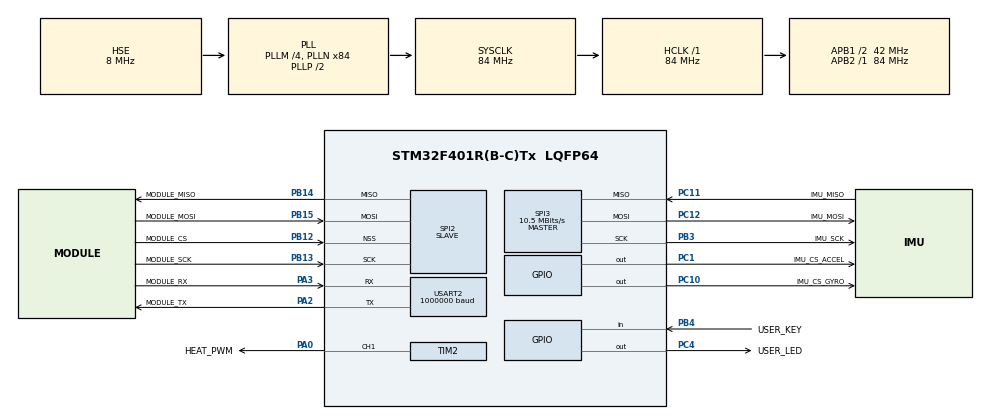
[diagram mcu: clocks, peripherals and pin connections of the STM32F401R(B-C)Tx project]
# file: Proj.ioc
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Dma.Request0=SPI2_RX
Dma.Request1=SPI2_TX
Dma.SPI2_RX.0.Direction=DMA_PERIPH_TO_MEMORY
Dma.SPI2_RX.0.FIFOMode=DMA_FIFOMODE_DISABLE
Dma.SPI2_RX.0.Instance=DMA1_Stream3
Dma.SPI2_RX.0.MemDataAlignment=DMA_MDATAALIGN_BYTE
Dma.SPI2_RX.0.MemInc=DMA_MINC_ENABLE
Dma.SPI2_RX.0.Mode=DMA_NORMAL
Dma.SPI2_RX.0.PeriphDataAlignment=DMA_PDATAALIGN_BYTE
Dma.SPI2_RX.0.PeriphInc=DMA_PINC_DISABLE
Dma.SPI2_RX.0.Priority=DMA_PRIORITY_LOW
Dma.SPI2_TX.1.Direction=DMA_MEMORY_TO_PERIPH
Dma.SPI2_TX.1.FIFOMode=DMA_FIFOMODE_DISABLE
Dma.SPI2_TX.1.Instance=DMA1_Stream4
Dma.SPI2_TX.1.MemDataAlignment=DMA_MDATAALIGN_BYTE
Dma.SPI2_TX.1.MemInc=DMA_MINC_ENABLE
Dma.SPI2_TX.1.Mode=DMA_NORMAL
Dma.SPI2_TX.1.PeriphDataAlignment=DMA_PDATAALIGN_BYTE
Dma.SPI2_TX.1.PeriphInc=DMA_PINC_DISABLE
Dma.SPI2_TX.1.Priority=DMA_PRIORITY_LOW
FREERTOS.INCLUDE_vTaskDelayUntil=1
FREERTOS.Tasks01=defaultTask,0,128,StartDefaultTask,Default,NULL,Dynamic,NULL,NULL;UartComm,0,512,UartCommTask,As weak,NULL,Static,UartCommBuffer,UartCommControlBlock;SPIComm,0,512,SPICommTask,As weak,NULL,Static,SPICommBuffer,SPICommControlBlock;Inertial,2,1024,InertialTask,As weak,NULL,Static,InertialBuffer,InertialControlBlock
FREERTOS.configENABLE_FPU=1
Mcu.Family=STM32F4
Mcu.Name=STM32F401R(B-C)Tx
Mcu.Package=LQFP64
NVIC.DMA1_Stream3_IRQn=true\:5\:0\:false\:false\:true\:true\:false\:true\:true
NVIC.DMA1_Stream4_IRQn=true\:5\:0\:false\:false\:true\:true\:false\:true\:true
NVIC.PriorityGroup=NVIC_PRIORITYGROUP_4
NVIC.TIM1_TRG_COM_TIM11_IRQn=true\:5\:0\:false\:false\:true\:true\:true\:true\:true
NVIC.TIM1_UP_TIM10_IRQn=true\:15\:0\:false\:false\:true\:false\:false\:true\:true
NVIC.TimeBase=TIM1_UP_TIM10_IRQn
NVIC.TimeBaseIP=TIM10
NVIC.USART2_IRQn=true\:5\:0\:false\:false\:true\:true\:true\:true\:true
PA0-WKUP.GPIO_Label=HEAT_PWM
PA0-WKUP.Signal=S_TIM2_CH1_ETR
PA13.Mode=Serial_Wire
PA13.Signal=SYS_JTMS-SWDIO
PA14.Mode=Serial_Wire
PA14.Signal=SYS_JTCK-SWCLK
PA2.GPIO_Label=MODULE_TX
PA2.Mode=Asynchronous
PA2.Signal=USART2_TX
PA3.GPIO_Label=MODULE_RX
PA3.Mode=Asynchronous
PA3.Signal=USART2_RX
PB12.GPIO_Label=MODULE_CS
PB12.Mode=NSS_Signal_Hard_Input
PB12.Signal=SPI2_NSS
PB13.GPIO_Label=MODULE_SCK
PB13.Mode=Full_Duplex_Slave
PB13.Signal=SPI2_SCK
PB14.GPIO_Label=MODULE_MISO
PB14.Mode=Full_Duplex_Slave
PB14.Signal=SPI2_MISO
PB15.GPIO_Label=MODULE_MOSI
PB15.Mode=Full_Duplex_Slave
PB15.Signal=SPI2_MOSI
PB3.GPIO_Label=IMU_SCK
PB3.Mode=Full_Duplex_Master
PB3.Signal=SPI3_SCK
PB4.GPIO_Label=USER_KEY
PB4.GPIO_PuPd=GPIO_PULLUP
PB4.Signal=GPIO_Input
PC1.GPIO_Label=IMU_CS_ACCEL
PC1.GPIO_PuPd=GPIO_PULLUP
PC1.GPIO_Speed=GPIO_SPEED_FREQ_VERY_HIGH
PC1.PinState=GPIO_PIN_SET
PC1.Signal=GPIO_Output
PC10.GPIO_Label=IMU_CS_GYRO
PC10.GPIO_PuPd=GPIO_PULLUP
PC10.GPIO_Speed=GPIO_SPEED_FREQ_VERY_HIGH
PC10.PinState=GPIO_PIN_SET
PC10.Signal=GPIO_Output
PC11.GPIO_Label=IMU_MISO
PC11.Mode=Full_Duplex_Master
PC11.Signal=SPI3_MISO
PC12.GPIO_Label=IMU_MOSI
PC12.Mode=Full_Duplex_Master
PC12.Signal=SPI3_MOSI
PC4.GPIO_Label=USER_LED
PC4.GPIO_PuPd=GPIO_PULLUP
PC4.PinState=GPIO_PIN_SET
PC4.Signal=GPIO_Output
PH0\ -\ OSC_IN.Mode=HSE-External-Oscillator
PH0\ -\ OSC_IN.Signal=RCC_OSC_IN
PH1\ -\ OSC_OUT.Mode=HSE-External-Oscillator
PH1\ -\ OSC_OUT.Signal=RCC_OSC_OUT
ProjectManager.HeapSize=0x200
ProjectManager.StackSize=0x400
ProjectManager.TargetToolchain=MDK-ARM V5.32
RCC.48MHZClocksFreq_Value=42000000
RCC.AHBFreq_Value=84000000
RCC.APB1CLKDivider=RCC_HCLK_DIV2
RCC.APB1Freq_Value=42000000
RCC.APB1TimFreq_Value=84000000
RCC.APB2Freq_Value=84000000
RCC.APB2TimFreq_Value=84000000
RCC.CortexFreq_Value=84000000
RCC.HCLKFreq_Value=84000000
RCC.HSE_VALUE=8000000
RCC.HSI_VALUE=16000000
RCC.LSE_VALUE=32768
RCC.PLLM=4
RCC.PLLN=84
RCC.PLLSourceVirtual=RCC_PLLSOURCE_HSE
RCC.SYSCLKFreq_VALUE=84000000
RCC.SYSCLKSource=RCC_SYSCLKSOURCE_PLLCLK
RCC.VCOOutputFreq_Value=168000000
SH.S_TIM2_CH1_ETR.0=TIM2_CH1,PWM Generation1 CH1
SPI2.CLKPhase=SPI_PHASE_2EDGE
SPI2.CLKPolarity=SPI_POLARITY_HIGH
SPI2.Direction=SPI_DIRECTION_2LINES
SPI2.Mode=SPI_MODE_SLAVE
SPI2.VirtualNSS=VM_NSSHARD
SPI2.VirtualType=VM_SLAVE
SPI3.BaudRatePrescaler=SPI_BAUDRATEPRESCALER_4
SPI3.CLKPhase=SPI_PHASE_2EDGE
SPI3.CLKPolarity=SPI_POLARITY_HIGH
SPI3.CalculateBaudRate=10.5 MBits/s
SPI3.Direction=SPI_DIRECTION_2LINES
SPI3.Mode=SPI_MODE_MASTER
SPI3.VirtualType=VM_MASTER
STMicroelectronics.X-CUBE-ALGOBUILD.1.5.0.LibraryCcDSPOoLibraryJjDSPOoLibrary=true
TIM11.Period=999
TIM11.Prescaler=83
TIM2.AutoReloadPreload=TIM_AUTORELOAD_PRELOAD_ENABLE
TIM2.Channel-PWM\ Generation1\ CH1=TIM_CHANNEL_1
TIM2.Period=1999
TIM2.Prescaler=83
USART2.BaudRate=1000000
USART2.VirtualMode=VM_ASYNC
VP_FREERTOS_VS_CMSIS_V1.Mode=CMSIS_V1
VP_STMicroelectronics.X-CUBE-ALGOBUILD_VS_DSPOoLibraryJjLibrary_1.5.0_1.5.0.Mode=DSPOoLibraryJjLibrary
VP_SYS_VS_tim10.Mode=TIM10
VP_TIM11_VS_ClockSourceINT.Mode=Enable_Timer
VP_TIM9_VS_ClockSourceINT.Mode=Internal
board=custom

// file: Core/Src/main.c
/* USER CODE BEGIN Header */
/**
  ******************************************************************************
  * @file           : main.c
  * @brief          : Main program body
  ******************************************************************************
  * @attention
  *
  * Copyright (c) 2026 STMicroelectronics.
  * All rights reserved.
  *
  * This software is licensed under terms that can be found in the LICENSE file
  * in the root directory of this software component.
  * If no LICENSE file comes with this software, it is provided AS-IS.
  *
  ******************************************************************************
  */
/* USER CODE END Header */
#include "main.h"
#include "cmsis_os.h"
#include "dma.h"
#include "spi.h"
#include "tim.h"
#include "usart.h"
#include "gpio.h"

/* USER CODE BEGIN PV */
uint32_t TimeStamp=0;

/* USER CODE END PV */

void SystemClock_Config(void);
void MX_FREERTOS_Init(void);

int main(void)
{

  /* MCU Configuration--------------------------------------------------------*/

  /* Reset of all peripherals, Initializes the Flash interface and the Systick. */
  HAL_Init();

  /* Configure the system clock */
  SystemClock_Config();

  /* Initialize all configured peripherals */
  MX_GPIO_Init();
  MX_DMA_Init();
  MX_TIM11_Init();
  MX_SPI2_Init();
  MX_SPI3_Init();
  MX_USART2_UART_Init();
  MX_TIM2_Init();
  MX_TIM9_Init();
  /* USER CODE BEGIN 2 */
	HAL_TIM_Base_Start_IT(&htim11);

  /* USER CODE END 2 */

  /* Call init function for freertos objects (in cmsis_os2.c) */
  MX_FREERTOS_Init();

  /* Start scheduler */
  osKernelStart();

  /* We should never get here as control is now taken by the scheduler */

  /* Infinite loop */
  while (1)
  {

  }
}

void SystemClock_Config(void)
{
  RCC_OscInitTypeDef RCC_OscInitStruct = {0};
  RCC_ClkInitTypeDef RCC_ClkInitStruct = {0};

  /** Configure the main internal regulator output voltage
  */
  __HAL_RCC_PWR_CLK_ENABLE();
  __HAL_PWR_VOLTAGESCALING_CONFIG(PWR_REGULATOR_VOLTAGE_SCALE2);

  /** Initializes the RCC Oscillators according to the specified parameters
  * in the RCC_OscInitTypeDef structure.
  */
  RCC_OscInitStruct.OscillatorType = RCC_OSCILLATORTYPE_HSE;
  RCC_OscInitStruct.HSEState = RCC_HSE_ON;
  RCC_OscInitStruct.PLL.PLLState = RCC_PLL_ON;
  RCC_OscInitStruct.PLL.PLLSource = RCC_PLLSOURCE_HSE;
  RCC_OscInitStruct.PLL.PLLM = 4;
  RCC_OscInitStruct.PLL.PLLN = 84;
  RCC_OscInitStruct.PLL.PLLP = RCC_PLLP_DIV2;
  RCC_OscInitStruct.PLL.PLLQ = 4;
  if (HAL_RCC_OscConfig(&RCC_OscInitStruct) != HAL_OK)
  {
    Error_Handler();
  }

  /** Initializes the CPU, AHB and APB buses clocks
  */
  RCC_ClkInitStruct.ClockType = RCC_CLOCKTYPE_HCLK|RCC_CLOCKTYPE_SYSCLK
                              |RCC_CLOCKTYPE_PCLK1|RCC_CLOCKTYPE_PCLK2;
  RCC_ClkInitStruct.SYSCLKSource = RCC_SYSCLKSOURCE_PLLCLK;
  RCC_ClkInitStruct.AHBCLKDivider = RCC_SYSCLK_DIV1;
  RCC_ClkInitStruct.APB1CLKDivider = RCC_HCLK_DIV2;
  RCC_ClkInitStruct.APB2CLKDivider = RCC_HCLK_DIV1;

  if (HAL_RCC_ClockConfig(&RCC_ClkInitStruct, FLASH_LATENCY_2) != HAL_OK)
  {
    Error_Handler();
  }
}

void HAL_TIM_PeriodElapsedCallback(TIM_HandleTypeDef *htim)
{
  if (htim->Instance == TIM10)
  {
    HAL_IncTick();
  }
  /* USER CODE BEGIN Callback 1 */

	 if (htim->Instance == TIM11)
    {
        TimeStamp++;
    }

  /* USER CODE END Callback 1 */
}

void Error_Handler(void)
{
  __disable_irq();
  while (1)
  {
  }
}

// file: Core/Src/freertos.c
/* USER CODE BEGIN Header */
/**
  ******************************************************************************
  * File Name          : freertos.c
  * Description        : Code for freertos applications
  ******************************************************************************
  * @attention
  *
  * Copyright (c) 2026 STMicroelectronics.
  * All rights reserved.
  *
  * This software is licensed under terms that can be found in the LICENSE file
  * in the root directory of this software component.
  * If no LICENSE file comes with this software, it is provided AS-IS.
  *
  ******************************************************************************
  */
/* USER CODE END Header */

#include "FreeRTOS.h"
#include "task.h"
#include "main.h"
#include "cmsis_os.h"

osThreadId defaultTaskHandle;
osThreadId UartCommHandle;
uint32_t UartCommBuffer[ 512 ];
osStaticThreadDef_t UartCommControlBlock;
osThreadId SPICommHandle;
uint32_t SPICommBuffer[ 512 ];
osStaticThreadDef_t SPICommControlBlock;
osThreadId InertialHandle;
uint32_t InertialBuffer[ 1024 ];
osStaticThreadDef_t InertialControlBlock;

void StartDefaultTask(void const * argument);
void UartCommTask(void const * argument);
void SPICommTask(void const * argument);
void InertialTask(void const * argument);

void MX_FREERTOS_Init(void); /* (MISRA C 2004 rule 8.1) */

/* GetIdleTaskMemory prototype (linked to static allocation support) */
void vApplicationGetIdleTaskMemory( StaticTask_t **ppxIdleTaskTCBBuffer, StackType_t **ppxIdleTaskStackBuffer, uint32_t *pulIdleTaskStackSize );

/* USER CODE BEGIN GET_IDLE_TASK_MEMORY */
static StaticTask_t xIdleTaskTCBBuffer;
static StackType_t xIdleStack[configMINIMAL_STACK_SIZE];

void vApplicationGetIdleTaskMemory( StaticTask_t **ppxIdleTaskTCBBuffer, StackType_t **ppxIdleTaskStackBuffer, uint32_t *pulIdleTaskStackSize )
{
  *ppxIdleTaskTCBBuffer = &xIdleTaskTCBBuffer;
  *ppxIdleTaskStackBuffer = &xIdleStack[0];
  *pulIdleTaskStackSize = configMINIMAL_STACK_SIZE;
  /* place for user code */
}
/* USER CODE END GET_IDLE_TASK_MEMORY */

void MX_FREERTOS_Init(void) {

  /* Create the thread(s) */
  /* definition and creation of defaultTask */
  osThreadDef(defaultTask, StartDefaultTask, osPriorityNormal, 0, 128);
  defaultTaskHandle = osThreadCreate(osThread(defaultTask), NULL);

  /* definition and creation of UartComm */
  osThreadStaticDef(UartComm, UartCommTask, osPriorityNormal, 0, 512, UartCommBuffer, &UartCommControlBlock);
  UartCommHandle = osThreadCreate(osThread(UartComm), NULL);

  /* definition and creation of SPIComm */
  osThreadStaticDef(SPIComm, SPICommTask, osPriorityNormal, 0, 512, SPICommBuffer, &SPICommControlBlock);
  SPICommHandle = osThreadCreate(osThread(SPIComm), NULL);

  /* definition and creation of Inertial */
  osThreadStaticDef(Inertial, InertialTask, osPriorityHigh, 0, 1024, InertialBuffer, &InertialControlBlock);
  InertialHandle = osThreadCreate(osThread(Inertial), NULL);

}

void StartDefaultTask(void const * argument)
{
  for(;;)
  {
    osDelay(1);
  }
}

__weak void UartCommTask(void const * argument)
{
  for(;;)
  {
    osDelay(1);
  }
}

__weak void SPICommTask(void const * argument)
{
  for(;;)
  {
    osDelay(1);
  }
}

__weak void InertialTask(void const * argument)
{
  for(;;)
  {
    osDelay(1);
  }
}
